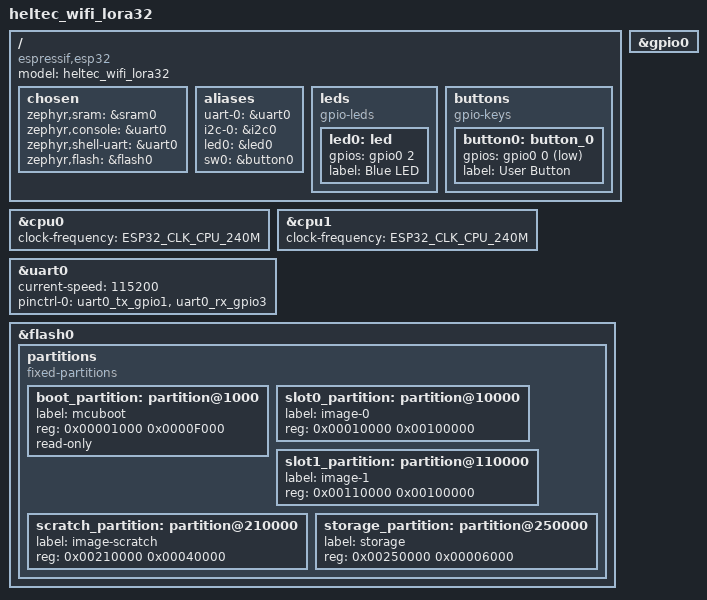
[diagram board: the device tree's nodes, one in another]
// Copyright (c) 2022 Tobias Piep
// SPDX-License-Identifier: Apache-2.0

/dts-v1/;

#include <espressif/esp32.dtsi>
#include "nodemcu_esp_32s_kit-pinctrl.dtsi"

/ {
	model = "heltec_wifi_lora32";
	compatible = "espressif,esp32";

	chosen {
		zephyr,sram = &sram0;
		zephyr,console = &uart0;
		zephyr,shell-uart = &uart0;
		zephyr,flash = &flash0;
	};

	aliases {
		uart-0 = &uart0;
		i2c-0 = &i2c0;
		led0 = &led0;
		sw0 = &button0;
	};

	leds {
		compatible = "gpio-leds";
		led0: led {
			gpios = <&gpio0 2 GPIO_ACTIVE_HIGH>;
			label = "Blue LED";
		};
	};

	buttons {
		compatible = "gpio-keys";
		button0: button_0 {
			gpios = < &gpio0 0 GPIO_ACTIVE_LOW>;
			label = "User Button";
		};
	};
};

&cpu0 {
	clock-frequency = <ESP32_CLK_CPU_240M>;
};

&cpu1 {
	clock-frequency = <ESP32_CLK_CPU_240M>;
};

&uart0 {
	status = "okay";
	current-speed = <115200>;
	pinctrl-0 = <&uart0_tx_gpio1 &uart0_rx_gpio3>;
	pinctrl-names = "default";
};

&gpio0 {
	status = "okay";
};

&flash0 {
	status = "okay";
	partitions {
		compatible = "fixed-partitions";
		#address-cells = <1>;
		#size-cells = <1>;

		/* Reserve 60kB for the bootloader */
		boot_partition: partition@1000 {
			label = "mcuboot";
			reg = <0x00001000 0x0000F000>;
			read-only;
		};

		/* Reserve 1024kB for the application in slot 0 */
		slot0_partition: partition@10000 {
			label = "image-0";
			reg = <0x00010000 0x00100000>;
		};

		/* Reserve 1024kB for the application in slot 1 */
		slot1_partition: partition@110000 {
			label = "image-1";
			reg = <0x00110000 0x00100000>;
		};

		/* Reserve 256kB for the scratch partition */
		scratch_partition: partition@210000 {
			   label = "image-scratch";
			   reg = <0x00210000 0x00040000>;
		};

		storage_partition: partition@250000 {
			label = "storage";
			reg = <0x00250000 0x00006000>;
		};
	};
};
